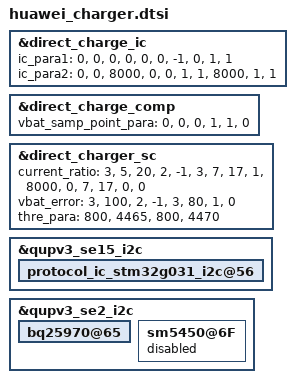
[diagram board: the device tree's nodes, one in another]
&direct_charge_ic {
	/* The IC_PARA table is used to find the relationship between chip and path */
	/* the chip's current passing capacity */
	/* and the sampling points of battery voltage and current */
	/* ic_index  path_index  max_ibat  ibat_sample_point  vbat_sample_point */
	ic_para1 =
		"0", "0", "0", "0", "0",
		"0", "-1", "0", "1", "1";
	ic_para2 =
		"0", "0", "8000", "0", "0",
		"1", "1", "8000", "1", "1";
	status = "ok";
};

&direct_charge_comp {
	vbat_samp_point_para =
		"0", "0", "0",
		"1", "1", "0";
};

&direct_charger_sc {
        current_ratio =
                "3", "5", "20", "2", "-1",
                "3", "7", "17", "1", "8000",
                "0", "7", "17", "0", "0";
        vbat_error =
                "3", "100", "2", "-1",
                "3", "80", "1", "0";
        thre_para =
                "800", "4465",
                "800", "4470";
};
&qupv3_se15_i2c {
	protocol_ic_stm32g031_i2c@56 {
		status = "ok";
	};
};

&qupv3_se2_i2c {
	bq25970@65 {
		status = "ok";
	};

	sm5450@6F{
		status = "disabled";
	};
};
